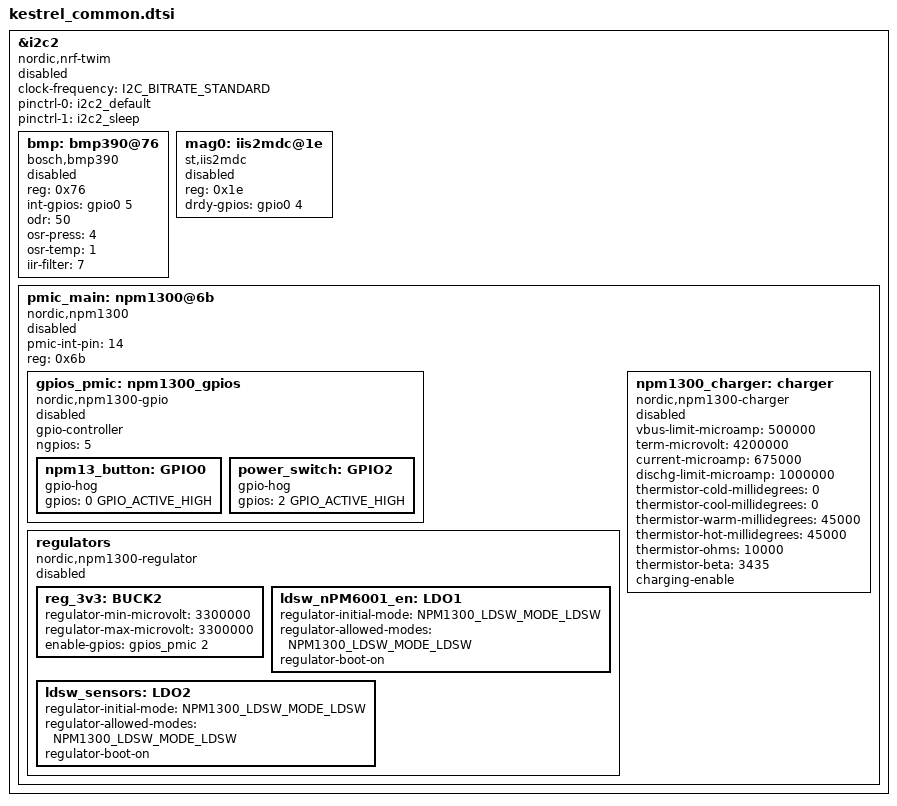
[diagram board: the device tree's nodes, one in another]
/*
 * Copyright (c) 2024 Nordic Semiconductor
 * SPDX-License-Identifier: LicenseRef-Nordic-5-Clause
 */

#include <dt-bindings/regulator/npm1300.h>
#include <zephyr/dt-bindings/sensor/icm42688.h>



&i2c2 {
	compatible = "nordic,nrf-twim";
	status = "disabled";
	clock-frequency = <I2C_BITRATE_STANDARD>;
	
	pinctrl-0 = <&i2c2_default>;
	pinctrl-1 = <&i2c2_sleep>;
	pinctrl-names = "default", "sleep";

	bmp: bmp390@76 {
        compatible = "bosch,bmp390";
        reg = <0x76>;
        status = "disabled";
        int-gpios = <&gpio0 5 GPIO_ACTIVE_HIGH>;
        odr = "50";      
        osr-press = <4>;     
        osr-temp  = <1>;    
        iir-filter = <7>;   
    };

	mag0: iis2mdc@1e {
        compatible = "st,iis2mdc";
        reg = <0x1e>;
        status = "disabled";
        drdy-gpios = <&gpio0 4 GPIO_ACTIVE_HIGH>;

    };

	pmic_main: npm1300@6b {
		compatible = "nordic,npm1300";
		status = "disabled";
		pmic-int-pin = <14>;
		reg = <0x6b>;

		
		gpios_pmic: npm1300_gpios {
			compatible = "nordic,npm1300-gpio";
			status = "disabled";
			gpio-controller;
			#gpio-cells = <2>;
			ngpios = <5>;
			npm13_button: GPIO0 {
				gpio-hog;
				gpios = <0 GPIO_ACTIVE_HIGH>;
			};
		
			power_switch: GPIO2 {
				gpio-hog;
				gpios = <2 GPIO_ACTIVE_HIGH>;
			};
			
		};

		regulators {
			compatible = "nordic,npm1300-regulator";
			status = "disabled";
			reg_3v3: BUCK2 {
				regulator-min-microvolt = <3300000>;
				regulator-max-microvolt = <3300000>;
				enable-gpios = <&gpios_pmic 2 GPIO_ACTIVE_HIGH>;
			};
			ldsw_nPM6001_en: LDO1 {
				regulator-initial-mode = <NPM1300_LDSW_MODE_LDSW>;
				regulator-allowed-modes = <NPM1300_LDSW_MODE_LDSW>;
				regulator-boot-on;
			};
			ldsw_sensors: LDO2 {
				regulator-initial-mode = <NPM1300_LDSW_MODE_LDSW>;
				regulator-allowed-modes = <NPM1300_LDSW_MODE_LDSW>;
				regulator-boot-on;
			};
		};

		npm1300_charger: charger {
			compatible = "nordic,npm1300-charger";
			status = "disabled";
			vbus-limit-microamp = <500000>;
			term-microvolt = <4200000>;
			current-microamp = <675000>; 
			dischg-limit-microamp = <1000000>; 
			thermistor-cold-millidegrees = <0>;
			thermistor-cool-millidegrees = <0>;
			thermistor-warm-millidegrees = <45000>;
			thermistor-hot-millidegrees = <45000>;
			thermistor-ohms = <10000>;
			thermistor-beta = <3435>;
			charging-enable;
		};

		
	};

	


};
